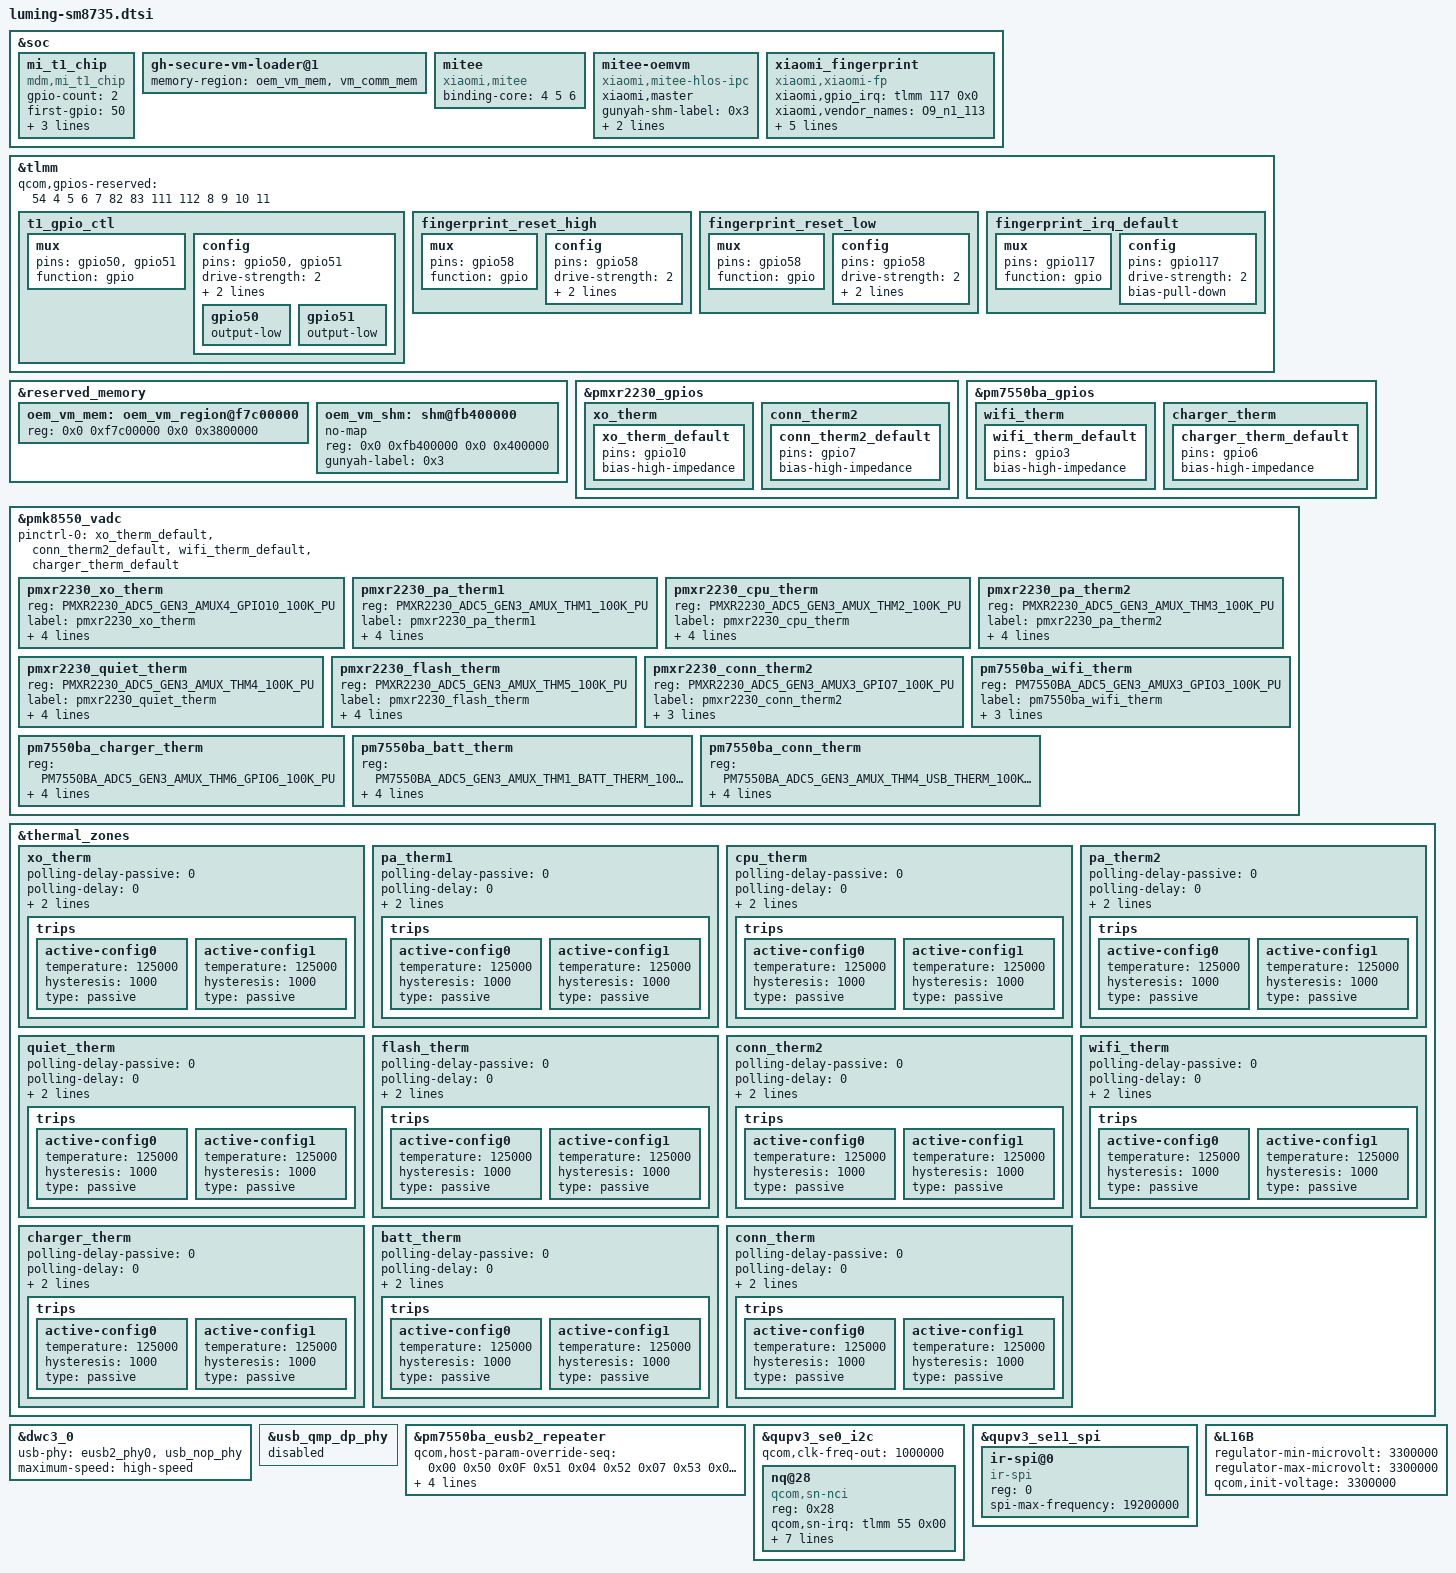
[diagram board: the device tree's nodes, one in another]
/*
  this file is for attribution only of luming
  And public attribution of xiaomi platforms(like O10U and so on)
*/
#include "luming-pinctrl.dtsi"
#include "sm8735-xiaomi-common.dtsi"
#include <dt-bindings/iio/qcom,spmi-adc5-gen3-pm7550ba.h>
#include <dt-bindings/iio/qcom,spmi-adc5-gen3-pmxr2230.h>
#include "luming-charger-common.dtsi"
#include "luming-xiaomi-touch-pinctrl.dtsi"


&soc {
	mi_t1_chip {
		compatible = "mdm,mi_t1_chip";
		gpio-count = <2>;
		first-gpio = <50>;
		mi-t1-gpio-1 = <&tlmm 50 0x0>;
		mi-t1-gpio-2 = <&tlmm 51 0x0>;
		    pinctrl-0 = <&t1_gpio_ctl>;
	};
};
&tlmm {
	/*t1s gpio config*/
	t1_gpio_ctl: t1_gpio_ctl {
		mux {
			pins = "gpio50", "gpio51";
			function = "gpio";
		};
		config {
			pins = "gpio50", "gpio51";
			drive-strength = <2>;
			bias-disable;
			output-enable;
			gpio50 {
			output-low;
			};
			gpio51 {
			output-low;
			};
		};
	};
};

/* mitee vm */
&reserved_memory {
	oem_vm_mem: oem_vm_region@f7c00000 {
		reg = <0x0 0xf7c00000 0x0 0x3800000>;
	};

	oem_vm_shm: shm@fb400000 {
		no-map;
		reg = <0x0 0xfb400000 0x0 0x400000>;
		gunyah-label = <0x3>;
	};
};

&soc {
	gh-secure-vm-loader@1 {
		memory-region = <&oem_vm_mem &vm_comm_mem>;
	};

	mitee: mitee {
		compatible = "xiaomi,mitee";
		binding-core = <4 5 6>;
	};

	mitee-oemvm {
		compatible = "xiaomi,mitee-hlos-ipc";
		xiaomi,master;
		gunyah-shm-label = <0x3>;
		peer-name = <0x4>;
		shared-buffer = <&oem_vm_shm>;
	};
};
/* mitee vm */

&pmxr2230_gpios {
    xo_therm {
            xo_therm_default: xo_therm_default {
            pins = "gpio10";
            bias-high-impedance;
            };
    };

	conn_therm2 {
		conn_therm2_default: conn_therm2_default {
		pins = "gpio7";
		bias-high-impedance;
		};
	};
};

&pm7550ba_gpios {
	wifi_therm {
		wifi_therm_default: wifi_therm_default {
		pins = "gpio3";
		bias-high-impedance;
		};
	};

	charger_therm {
		charger_therm_default: charger_therm_default {
		pins = "gpio6";
		bias-high-impedance;
		};
	};
};

&pmk8550_vadc {
	pinctrl-names = "default";
	pinctrl-0 =<&xo_therm_default>,<&conn_therm2_default>,<&wifi_therm_default>,<&charger_therm_default>;
	pmxr2230_xo_therm {
		reg = <PMXR2230_ADC5_GEN3_AMUX4_GPIO10_100K_PU>;
		label = "pmxr2230_xo_therm";
		qcom,ratiometric;
		qcom,hw-settle-time = <200>;
		qcom,pre-scaling = <1 1>;
		qcom,adc-tm-type = <1>;
	};

	pmxr2230_pa_therm1 {
		reg = <PMXR2230_ADC5_GEN3_AMUX_THM1_100K_PU>;
		label = "pmxr2230_pa_therm1";
		qcom,ratiometric;
		qcom,hw-settle-time = <200>;
		qcom,pre-scaling = <1 1>;
		qcom,adc-tm-type = <1>;
	};

	pmxr2230_cpu_therm {
		reg = <PMXR2230_ADC5_GEN3_AMUX_THM2_100K_PU>;
		label = "pmxr2230_cpu_therm";
		qcom,ratiometric;
		qcom,hw-settle-time = <200>;
		qcom,pre-scaling = <1 1>;
		qcom,adc-tm-type = <1>;
	};

	pmxr2230_pa_therm2 {
		reg = <PMXR2230_ADC5_GEN3_AMUX_THM3_100K_PU>;
		label = "pmxr2230_pa_therm2";
		qcom,ratiometric;
		qcom,hw-settle-time = <200>;
		qcom,pre-scaling = <1 1>;
		qcom,adc-tm-type = <1>;
	};

	pmxr2230_quiet_therm {
		reg = <PMXR2230_ADC5_GEN3_AMUX_THM4_100K_PU>;
		label = "pmxr2230_quiet_therm";
		qcom,ratiometric;
		qcom,hw-settle-time = <200>;
		qcom,pre-scaling = <1 1>;
		qcom,adc-tm-type = <1>;
	};

	pmxr2230_flash_therm {
		reg = <PMXR2230_ADC5_GEN3_AMUX_THM5_100K_PU>;
		label = "pmxr2230_flash_therm";
		qcom,ratiometric;
		qcom,hw-settle-time = <200>;
		qcom,pre-scaling = <1 1>;
		qcom,adc-tm-type = <1>;
	};

	pmxr2230_conn_therm2 {
		reg = <PMXR2230_ADC5_GEN3_AMUX3_GPIO7_100K_PU>;
		label = "pmxr2230_conn_therm2";
		qcom,ratiometric;
		qcom,pre-scaling = <1 1>;
		qcom,adc-tm-type = <1>;
	};

	pm7550ba_wifi_therm {
		reg = <PM7550BA_ADC5_GEN3_AMUX3_GPIO3_100K_PU>;
		label = "pm7550ba_wifi_therm";
		qcom,ratiometric;
		qcom,pre-scaling = <1 1>;
		qcom,adc-tm-type = <1>;
	};

	pm7550ba_charger_therm {
		reg = <PM7550BA_ADC5_GEN3_AMUX_THM6_GPIO6_100K_PU>;
		label = "pm7550ba_charger_therm";
		qcom,ratiometric;
		qcom,pre-scaling = <1 1>;
		qcom,adc-tm-type = <1>;
	};

	pm7550ba_batt_therm {
		reg = <PM7550BA_ADC5_GEN3_AMUX_THM1_BATT_THERM_100K_PU>;
		label = "pm7550ba_batt_therm";
		qcom,ratiometric;
		qcom,pre-scaling = <1 1>;
		qcom,adc-tm-type = <1>;
	};

	pm7550ba_conn_therm {
		reg = <PM7550BA_ADC5_GEN3_AMUX_THM4_USB_THERM_100K_PU>;
		label = "pm7550ba_conn_therm";
		qcom,ratiometric;
		qcom,pre-scaling = <1 1>;
		qcom,adc-tm-type = <1>;
	};
};

&thermal_zones {
	xo_therm {
		polling-delay-passive = <0>;
		polling-delay = <0>;
		thermal-sensors = <&pmk8550_vadc PMXR2230_ADC5_GEN3_AMUX4_GPIO10_100K_PU>;
		trips {
			active-config0 {
				temperature = <125000>;
				hysteresis = <1000>;
				type = "passive";
			};
			active-config1 {
				temperature = <125000>;
				hysteresis = <1000>;
				type = "passive";
			};
		};
	};

	pa_therm1 {
		polling-delay-passive = <0>;
		polling-delay = <0>;
		thermal-sensors = <&pmk8550_vadc PMXR2230_ADC5_GEN3_AMUX_THM1_100K_PU>;
		trips {
			active-config0 {
				temperature = <125000>;
				hysteresis = <1000>;
				type = "passive";
			};
			active-config1 {
				temperature = <125000>;
				hysteresis = <1000>;
				type = "passive";
			};
		};
	};

	cpu_therm {
		polling-delay-passive = <0>;
		polling-delay = <0>;
		thermal-sensors = <&pmk8550_vadc PMXR2230_ADC5_GEN3_AMUX_THM2_100K_PU>;
		trips {
			active-config0 {
				temperature = <125000>;
				hysteresis = <1000>;
				type = "passive";
			};
			active-config1 {
				temperature = <125000>;
				hysteresis = <1000>;
				type = "passive";
			};
		};
	};

	pa_therm2 {
		polling-delay-passive = <0>;
		polling-delay = <0>;
		thermal-sensors = <&pmk8550_vadc PMXR2230_ADC5_GEN3_AMUX_THM3_100K_PU>;
		trips {
			active-config0 {
				temperature = <125000>;
				hysteresis = <1000>;
				type = "passive";
			};
			active-config1 {
				temperature = <125000>;
				hysteresis = <1000>;
				type = "passive";
			};
		};
	};

	quiet_therm {
		polling-delay-passive = <0>;
		polling-delay = <0>;
		thermal-sensors = <&pmk8550_vadc PMXR2230_ADC5_GEN3_AMUX_THM4_100K_PU>;
		trips {
			active-config0 {
				temperature = <125000>;
				hysteresis = <1000>;
				type = "passive";
			};
			active-config1 {
				temperature = <125000>;
				hysteresis = <1000>;
				type = "passive";
			};
		};
	};

	flash_therm {
		polling-delay-passive = <0>;
		polling-delay = <0>;
		thermal-sensors = <&pmk8550_vadc PMXR2230_ADC5_GEN3_AMUX_THM5_100K_PU>;
		trips {
			active-config0 {
				temperature = <125000>;
				hysteresis = <1000>;
				type = "passive";
			};
			active-config1 {
				temperature = <125000>;
				hysteresis = <1000>;
				type = "passive";
			};
		};
	};

	conn_therm2 {
		polling-delay-passive = <0>;
		polling-delay = <0>;
		thermal-sensors = <&pmk8550_vadc PMXR2230_ADC5_GEN3_AMUX3_GPIO7_100K_PU>;
		trips {
			active-config0 {
				temperature = <125000>;
				hysteresis = <1000>;
				type = "passive";
			};
			active-config1 {
				temperature = <125000>;
				hysteresis = <1000>;
				type = "passive";
			};
		};
	};

	wifi_therm {
		polling-delay-passive = <0>;
		polling-delay = <0>;
		thermal-sensors = <&pmk8550_vadc PM7550BA_ADC5_GEN3_AMUX3_GPIO3_100K_PU>;
		trips {
			active-config0 {
				temperature = <125000>;
				hysteresis = <1000>;
				type = "passive";
			};
			active-config1 {
				temperature = <125000>;
				hysteresis = <1000>;
				type = "passive";
			};
		};
	};

	charger_therm {
		polling-delay-passive = <0>;
		polling-delay = <0>;
		thermal-sensors = <&pmk8550_vadc PM7550BA_ADC5_GEN3_AMUX_THM6_GPIO6_100K_PU>;
		trips {
			active-config0 {
				temperature = <125000>;
				hysteresis = <1000>;
				type = "passive";
			};
			active-config1 {
				temperature = <125000>;
				hysteresis = <1000>;
				type = "passive";
			};
		};
	};

	batt_therm {
		polling-delay-passive = <0>;
		polling-delay = <0>;
		thermal-sensors = <&pmk8550_vadc PM7550BA_ADC5_GEN3_AMUX_THM1_BATT_THERM_100K_PU>;
		trips {
			active-config0 {
				temperature = <125000>;
				hysteresis = <1000>;
				type = "passive";
			};
			active-config1 {
				temperature = <125000>;
				hysteresis = <1000>;
				type = "passive";
			};
		};
	};

	conn_therm {
		polling-delay-passive = <0>;
		polling-delay = <0>;
		thermal-sensors = <&pmk8550_vadc PM7550BA_ADC5_GEN3_AMUX_THM4_USB_THERM_100K_PU>;
		trips {
			active-config0 {
				temperature = <125000>;
				hysteresis = <1000>;
				type = "passive";
			};
			active-config1 {
				temperature = <125000>;
				hysteresis = <1000>;
				type = "passive";
			};
		};
	};
};

&dwc3_0 {
	usb-phy = <&eusb2_phy0>, <&usb_nop_phy>;
	maximum-speed = "high-speed";
};
&usb_qmp_dp_phy {
	status = "disabled";
};
&pm7550ba_eusb2_repeater {
	qcom,host-param-override-seq =
		<0x00 0x50
		0x0F 0x51
		0x04 0x52
		0x07 0x53
		0x02 0x54
		0x03 0x55
		0x00 0x56
		0x05 0x57
		0x02 0x58
		0x03 0x59
		0x03 0x5a
		0x02 0x5b>;
	qcom,param-override-seq =
		<0x00 0x50
		0x0D 0x51
		0x02 0x52
		0x07 0x53
		0x02 0x54
		0x03 0x55
		0x00 0x56
		0x07 0x57
		0x02 0x58
		0x03 0x59
		0x01 0x5a
		0x02 0x5b>;
	qcom,param-override-seq-host-ms =
		<0x00 0x50
		0x0F 0x51
		0x04 0x52
		0x07 0x53
		0x02 0x54
		0x03 0x55
		0x00 0x56
		0x05 0x57
		0x02 0x58
		0x03 0x59
		0x03 0x5a
		0x02 0x5b>;
};

&qupv3_se0_i2c {
	status = "ok";
	qcom,clk-freq-out = <1000000>;
	#address-cells = <1>;
	#size-cells = <0>;
	nq@28 {
		compatible = "qcom,sn-nci";
		reg = <0x28>;
		qcom,sn-irq = <&tlmm 55 0x00>;
		qcom,sn-ven = <&tlmm 114 0x00>;
		qcom,sn-clkreq = <&tlmm 115 0x00>;
		qcom,sn-szone = "enable";
		interrupt-parent = <&tlmm>;
		interrupts = <55 0>;
		interrupt-names = "nfc_irq";
		pinctrl-names = "nfc_active", "nfc_suspend";
		pinctrl-0 = <&nfc_int_active &nfc_enable_active>;
		pinctrl-1 = <&nfc_int_suspend &nfc_enable_suspend>;
	};
};

&qupv3_se11_spi {
	status = "ok";
	ir-spi@0 {
		compatible = "ir-spi";
		reg = <0>;
		spi-max-frequency = <19200000>;
		status = "ok";
        };
};

&soc {
        xiaomi_fingerprint {
                compatible = "xiaomi,xiaomi-fp";
                xiaomi,gpio_irq = <&tlmm 117 0x0>;
                xiaomi,vendor_names = "O9_n1_113"; //g3t 
                fp_3v3_vreg-supply = <&L16B>;
                netlink-event = <25>;
                pinctrl-names = "reset_high", "reset_low","irq_default";
                pinctrl-0 = <&fingerprint_reset_high>;
                pinctrl-1 = <&fingerprint_reset_low>;
                pinctrl-2 = <&fingerprint_irq_default>;
                status = "ok";
        };
};
&L16B {
        regulator-min-microvolt = <3300000>;
        regulator-max-microvolt = <3300000>;
        qcom,init-voltage = <3300000>;
};
&tlmm {
        /*FP spi gpio accessible to tz*/ 
        qcom,gpios-reserved = <54 4 5 6 7 82 83 111 112 8 9 10 11>;
        /* FP_RESET_HIGH, state device active*/
        fingerprint_reset_high: fingerprint_reset_high {
                mux {
                        pins = "gpio58";
                        function = "gpio";
                };
                config {
                        pins = "gpio58";
                        drive-strength = <2>;
                        bias-disable;
                        output-high;
                };
        };
        /* FP_RESET_LOW */
        fingerprint_reset_low: fingerprint_reset_low {
                mux {
                        pins = "gpio58";
                        function = "gpio";
                };
                config {
                        pins = "gpio58";
                        drive-strength = <2>;
                        bias-disable;
                        output-low;
                };
        };
        /* FP_INT_N */
        fingerprint_irq_default: fingerprint_irq_default {
                mux {
                        pins = "gpio117";
                        function = "gpio";
                };
                config {
                        pins = "gpio117";
                        drive-strength = <2>;
                        bias-pull-down;
                };
        };
};
